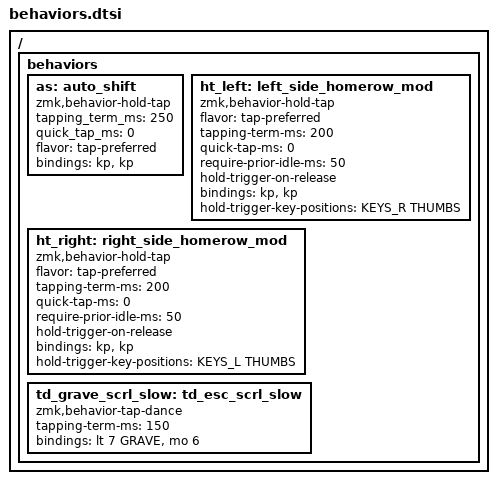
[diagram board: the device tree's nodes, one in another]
#define KEYS_L 0 1 2 3 4 5 12 13 14 15 16 17 24 25 26 27 28 29 36 37 38 19 20 21 22  // Left-hand keys.
#define KEYS_R 6 7 8 9 10 11 18 19 20 21 22 23 30 31 32 33 34 35 39 40 16 15 14 13  // Right-hand keys.
#define THUMBS 36 37 38 39 40  // Thumb keys.

#define AS(keycode) &as LS(keycode) keycode  // Autoshift Macro

/ {
    behaviors {

        as: auto_shift {
            compatible = "zmk,behavior-hold-tap";
            #binding-cells = <2>;
            tapping_term_ms = <250>;
            quick_tap_ms = <0>;
            flavor = "tap-preferred";
            bindings = <&kp>, <&kp>;
        };

        // Left-hand HRM
        ht_left: left_side_homerow_mod {
            compatible = "zmk,behavior-hold-tap";
            #binding-cells = <2>;
            flavor = "tap-preferred";
            tapping-term-ms = <200>;
            quick-tap-ms = <0>;
            require-prior-idle-ms = <50>;
            hold-trigger-on-release;
            bindings = <&kp>, <&kp>;
            hold-trigger-key-positions = <KEYS_R THUMBS>;
        };

        // Right-hand HRM
        ht_right: right_side_homerow_mod {
            compatible = "zmk,behavior-hold-tap";
            #binding-cells = <2>;
            flavor = "tap-preferred";
            tapping-term-ms = <200>;
            quick-tap-ms = <0>;
            require-prior-idle-ms = <50>;
            hold-trigger-on-release;
            bindings = <&kp>, <&kp>;
            hold-trigger-key-positions = <KEYS_L THUMBS>;
        };

        td_grave_scrl_slow: td_esc_scrl_slow {
            compatible = "zmk,behavior-tap-dance";
            #binding-cells = <0>;
            tapping-term-ms = <150>;
            bindings = <&lt 7 GRAVE>, <&mo 6>; // hold, tap, double_tap
        };
    };
};
